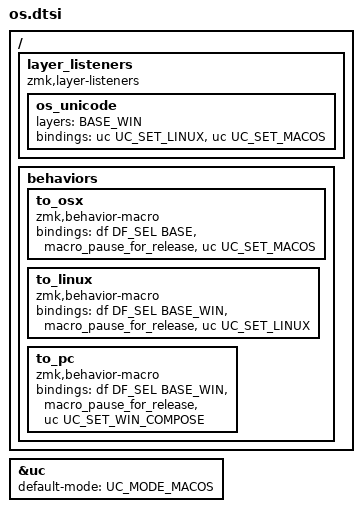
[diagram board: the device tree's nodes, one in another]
/* OS handling
 *
 * BASE is the macOS base layer; BASE_WIN is a transparent overlay with the
 * Linux/Windows differences. Which one is active is stored per endpoint (USB
 * and each BT profile) by the default-layer module and survives reboots.
 *
 * &df stores the choice for the endpoint that is active *when it runs*. A BT
 * profile only becomes the active endpoint once it is connected (before that
 * ZMK falls back to USB or NONE), so the to_* keys must be pressed while
 * connected to the host. Saves are debounced by 60s
 * (CONFIG_ZMK_SETTINGS_SAVE_DEBOUNCE) before they reach flash.
 *
 * Unicode input follows the layer through a layer listener: entering BASE_WIN
 * selects Linux input, leaving it selects macOS input. Windows (WinCompose) is
 * an explicit, non-persistent override via &to_pc.
 */

#include <behaviors/default_layer.dtsi> // requires zmk-feature-default-layer module
#include <dt-bindings/zmk_behavior_default_layer/default_layer.h>

&uc {
    default-mode = <UC_MODE_MACOS>;
};

/ {
    layer_listeners {
        compatible = "zmk,layer-listeners"; // requires zmk-listeners module

        os_unicode {
            layers = <BASE_WIN>;
            bindings = <&uc UC_SET_LINUX>, <&uc UC_SET_MACOS>;
        };
    };
};

// Select the OS for the current endpoint. The explicit unicode mode is set on
// release, so that it runs after the layer listener triggered on press.
ZMK_MACRO(to_osx,
    bindings
        = <&df DF_SEL BASE>
        , <&macro_pause_for_release>
        , <&uc UC_SET_MACOS>
        ;
)
ZMK_MACRO(to_linux,
    bindings
        = <&df DF_SEL BASE_WIN>
        , <&macro_pause_for_release>
        , <&uc UC_SET_LINUX>
        ;
)
ZMK_MACRO(to_pc,
    bindings
        = <&df DF_SEL BASE_WIN>
        , <&macro_pause_for_release>
        , <&uc UC_SET_WIN_COMPOSE>
        ;
)
